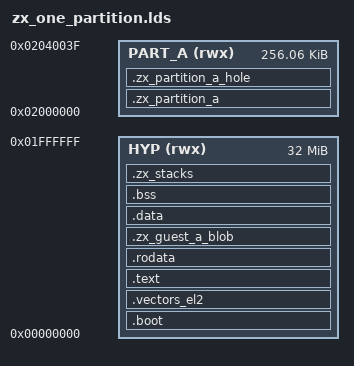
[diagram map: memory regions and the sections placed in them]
/***************************************************************************
 * Copyright (c) 2026 Eclipse ThreadX contributors
 *
 * This program and the accompanying materials are made available under the
 * terms of the MIT License which is available at
 * https://opensource.org/licenses/MIT.
 *
 * AI Disclosure: This file was largely AI-generated by Claude Code (Opus 5).
 * The AI-generated portions may be considered public domain (CC0-1.0)
 * and not subject to the project's licence. The human contributor has
 * reviewed and verified that the code is correct.
 *
 * SPDX-License-Identifier: MIT and CC0-1.0
 **************************************************************************/

/* Link map for the ZoneX one-partition image on the Armv8-R AEM FVP.
 *
 * WHY THIS IS A SECOND SCRIPT AND NOT AN EXTENSION OF zx_link.lds
 *
 * The two images describe genuinely different memory.  The stage-2 probe has
 * two small partition windows and a relocatable blob copied into both; this
 * one has a single 256 KB window holding a whole ThreadX, and it embeds a
 * guest image that the probe image does not have and must not require.
 *
 * Sharing one script would mean the probe carrying a KEEP for a section it
 * never supplies -- which produces an EMPTY section rather than an error,
 * silently, at whatever address the location counter held.  That is the exact
 * failure the loader's magic-number check exists to catch, and the right
 * place to avoid it is here.
 *
 * THE WINDOW ADDRESS IS A CONTRACT, NOT A CHOICE.  0x02000000 and 0x40000
 * are written into the guest's own linker script as well, because the guest
 * is LINKED for this window -- every absolute address inside it is baked in.
 * Changing either number means changing both, and the guest declares what it
 * was built for in its own image header so that a mismatch is REFUSED at
 * boot rather than discovered as a fault at a plausible-looking address.
 *
 * A NOTE ON ALIGN, because the two spellings are not equivalent
 *
 * Every ALIGN below is written AFTER the colon, which is the section's
 * ALIGNMENT.  Written before the colon it is the section's ADDRESS,
 * evaluated from a location counter that starts at zero, and it silently
 * overrides the region assignment.  Harmless where memory starts at zero and
 * catastrophic where it does not -- which is what makes it worth repeating
 * in every script here rather than in one of them.
 *
 * ZoneX's OWN code, data, bss and stack are covered by no region at all.
 * That is decision D2: with HSCTLR.BR=1 EL2's own accesses fall back to the
 * background map, while EL0/EL1 accesses that hit no region fault regardless
 * of BR -- so the hypervisor costs no region and is protected from the guest
 * precisely by not being mapped.
 */

ENTRY(_start)

__zx_hyp_stack_size = 0x1000;

/* THE PARTITION WINDOW.  Both numbers are duplicated in
   guest_a/link_partition_a.lds and the pair is checked at boot against the
   guest's own image header.  */

__zx_partition_a_base = 0x02000000;
__zx_partition_a_size = 0x00040000;

MEMORY
{
    /* Two regions rather than one location counter, so that the window's
       address is declared rather than arrived at.  A script that reached
       0x02000000 by assignment would place the window correctly today and
       silently move it the first time the hypervisor's own image grew past
       32 MB -- which is a change nobody would connect to a guest that
       stopped working.  */

    HYP    (rwx) : ORIGIN = 0x00000000, LENGTH = 0x02000000    /* 32 MB    */
    PART_A (rwx) : ORIGIN = 0x02000000, LENGTH = 0x00040040    /* + a hole */
}

SECTIONS
{
    . = ALIGN(64);

    .boot :
    {
        KEEP(*(.text.boot))
    } > HYP

    .vectors_el2 :
    {
        KEEP(*(.vectors_el2))
    } > HYP

    .text :
    {
        *(.text*)
        *(.glue_7)
        *(.glue_7t)
    } > HYP

    .rodata :
    {
        . = ALIGN(4);
        *(.rodata*)
        . = ALIGN(4);
    } > HYP

    /* ------------------------------------------------------------------
       THE GUEST IMAGE, in the hypervisor's own memory.

       Covered by no stage-2 region, exactly like the rest of ZoneX, so a
       running partition cannot read the image it was loaded from -- which
       matters more than it looks: a partition able to read its own source
       image could also read the NEXT partition's, and the isolation claim
       would be about the copies rather than about the originals.
       ------------------------------------------------------------------ */

    .zx_guest_a_blob : ALIGN(64)
    {
        __zx_guest_a_blob_start = .;
        KEEP(*(.zx_guest_a_blob))
        . = ALIGN(4);
        __zx_guest_a_blob_end = .;
    } > HYP

    .data : ALIGN(64)
    {
        __zx_data_start = .;
        *(.data*)
        . = ALIGN(4);
        __zx_data_end = .;
    } > HYP

    .bss (NOLOAD) : ALIGN(64)
    {
        __zx_bss_start = .;
        *(.bss*)
        *(COMMON)
        . = ALIGN(4);
        __zx_bss_end = .;
    } > HYP

    /* SP must stay 8-byte aligned (AAPCS), so the area is aligned before
       its top symbol is taken.  */

    .zx_stacks (NOLOAD) :
    {
        . = ALIGN(8);
        . = . + __zx_hyp_stack_size;
        __zx_hyp_stack_top = .;
    } > HYP

    . = ALIGN(8);
    _end = .;
    PROVIDE(end = .);

    /* ------------------------------------------------------------------
       PARTITION A'S WINDOW, and the ungranted granule after it.

       NOLOAD: there is nothing in this ELF to load here.  The contents
       arrive at run time, when the loader copies the guest image in, which
       is the path a real guest takes and the reason the manifest's
       image_start and image_end are load-bearing rather than decorative.

       THE HOLE IS ADJACENT BY CONSTRUCTION and the ASSERT keeps it that
       way.  An ungranted address far from every grant proves only that
       unmapped memory faults; the defect class worth catching is a region
       whose limit is out by ONE GRANULE, and only an adjacent hole catches
       it.
       ------------------------------------------------------------------ */

    .zx_partition_a (NOLOAD) : ALIGN(64)
    {
        __zx_partition_a_start = .;
        . = . + __zx_partition_a_size;
        __zx_partition_a_end = .;
    } > PART_A

    .zx_partition_a_hole (NOLOAD) : ALIGN(64)
    {
        __zx_partition_a_hole_start = .;
        . = . + 64;
        __zx_partition_a_hole_end = .;
    } > PART_A

    /* ------------------------------------------------------------------
       Assert the geometry the region programming and the loader depend on,
       so that a layout mistake fails the LINK rather than the run.  A
       region whose base is under-aligned does not fault: its low bits land
       on SH, AP and XN and silently change what it grants, which is the
       single hardest failure in this architecture to see.
       ------------------------------------------------------------------ */

    ASSERT((__zx_partition_a_start & 63) == 0,
           "partition A's window base is not 64-byte aligned")
    ASSERT((__zx_partition_a_end & 63) == 0,
           "partition A's window is not a whole number of granules")
    ASSERT(__zx_partition_a_start == __zx_partition_a_base,
           "partition A's window is not at the address the guest was linked for")
    ASSERT(__zx_partition_a_hole_start == __zx_partition_a_end,
           "the ungranted granule is NOT adjacent to partition A's window")

    ASSERT((__zx_guest_a_blob_start & 63) == 0,
           "the guest image is not 64-byte aligned")

    /* THE BLOB IS NOT EMPTY, and this is the check that catches an .incbin
       whose file was missing or a linker input pattern that matched
       nothing.  Asserted against the size of the image header rather than
       against zero, because a blob too small to carry its own header is
       just as useless as one of no size at all -- and the loader's magic
       check would then be reading past the end of the section.  */

    ASSERT((__zx_guest_a_blob_end - __zx_guest_a_blob_start) > 0x50,
           "the embedded guest image is empty or too small to carry its header")

    ASSERT((__zx_guest_a_blob_end - __zx_guest_a_blob_start)
               <= __zx_partition_a_size,
           "the embedded guest image does not fit partition A's window")

    /* And the hypervisor's own image must not have reached the window.  The
       two MEMORY regions make this impossible rather than merely unlikely,
       so this asserts the thing the reader would otherwise have to work out
       from the region lengths.  */

    ASSERT(_end <= __zx_partition_a_base,
           "the hypervisor's own image has grown into partition A's window")
}
